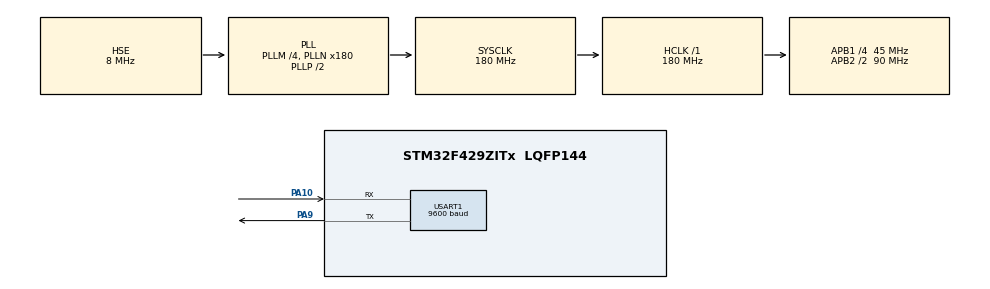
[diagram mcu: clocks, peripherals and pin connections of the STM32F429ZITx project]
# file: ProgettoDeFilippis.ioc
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ADC1.Channel-0\#ChannelRegularConversion=ADC_CHANNEL_TEMPSENSOR
ADC1.ClockPrescaler=ADC_CLOCK_SYNC_PCLK_DIV4
ADC1.ContinuousConvMode=DISABLE
ADC1.DMAContinuousRequests=DISABLE
ADC1.DataAlign=ADC_DATAALIGN_RIGHT
ADC1.DiscontinuousConvMode=DISABLE
ADC1.EOCSelection=ADC_EOC_SINGLE_CONV
ADC1.EnableAnalogWatchDog=false
ADC1.ExternalTrigConv=ADC_EXTERNALTRIGCONV_T2_TRGO
ADC1.ExternalTrigConvEdge=ADC_EXTERNALTRIGCONVEDGE_RISING
ADC1.InjNumberOfConversion=0
ADC1.NbrOfConversion=1
ADC1.NbrOfConversionFlag=1
ADC1.Rank-0\#ChannelRegularConversion=1
ADC1.Resolution=ADC_RESOLUTION_12B
ADC1.SamplingTime-0\#ChannelRegularConversion=ADC_SAMPLETIME_3CYCLES
ADC1.ScanConvMode=DISABLE
ADC1.master=1
Mcu.Family=STM32F4
Mcu.Name=STM32F429ZITx
Mcu.Package=LQFP144
NVIC.ADC_IRQn=true\:0\:0\:false\:false\:true\:true
NVIC.PriorityGroup=NVIC_PRIORITYGROUP_4
NVIC.TIM2_IRQn=true\:0\:0\:false\:false\:true\:true
PA10.Mode=Asynchronous
PA10.Signal=USART1_RX
PA9.Mode=Asynchronous
PA9.Signal=USART1_TX
PH0/OSC_IN.Mode=HSE-External-Oscillator
PH0/OSC_IN.Signal=RCC_OSC_IN
PH1/OSC_OUT.Mode=HSE-External-Oscillator
PH1/OSC_OUT.Signal=RCC_OSC_OUT
ProjectManager.HeapSize=0x200
ProjectManager.StackSize=0x400
ProjectManager.TargetToolchain=TrueSTUDIO
RCC.48MHZClocksFreq_Value=90000000
RCC.AHBFreq_Value=180000000
RCC.APB1CLKDivider=RCC_HCLK_DIV4
RCC.APB1Freq_Value=45000000
RCC.APB1TimFreq_Value=90000000
RCC.APB2CLKDivider=RCC_HCLK_DIV2
RCC.APB2Freq_Value=90000000
RCC.APB2TimFreq_Value=180000000
RCC.CortexFreq_Value=180000000
RCC.HCLKFreq_Value=180000000
RCC.HSE_VALUE=8000000
RCC.HSI_VALUE=16000000
RCC.LSE_VALUE=32768
RCC.PLLM=4
RCC.PLLN=180
RCC.PLLSourceVirtual=RCC_PLLSOURCE_HSE
RCC.SYSCLKFreq_VALUE=180000000
RCC.SYSCLKSource=RCC_SYSCLKSOURCE_PLLCLK
RCC.VCOOutputFreq_Value=360000000
TIM2.Period=4999
TIM2.Prescaler=9000
TIM2.TIM_MasterOutputTrigger=TIM_TRGO_UPDATE
USART1.BaudRate=9600
USART1.VirtualMode=VM_ASYNC
VP_ADC1_TempSens_Input.Mode=IN-TempSens
VP_TIM2_VS_ClockSourceINT.Mode=Internal
board=ProgettoDeFilippis

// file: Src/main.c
/**
  ******************************************************************************
  * @file           : main.c
  * @brief          : Main program body
  * ingroup 		: template
  * version 		: 1.0.0
  * date    		: 31/05/2018
  * author  		: Giovanni Caiazzo , Olawale Luqman Ajani, Luca Signorelli
  * defgroup 		: Matrix_Temperature
  *
  ******************************************************************************
  ** This notice applies to any and all portions of this file
  * that are not between comment pairs USER CODE BEGIN and
  * USER CODE END. Other portions of this file, whether
  * inserted by the user or by software development tools
  * are owned by their respective copyright owners.
  *
  * COPYRIGHT(c) 2018 STMicroelectronics
  *
  * Redistribution and use in source and binary forms, with or without modification,
  * are permitted provided that the following conditions are met:
  *   1. Redistributions of source code must retain the above copyright notice,
  *      this list of conditions and the following disclaimer.
  *   2. Redistributions in binary form must reproduce the above copyright notice,
  *      this list of conditions and the following disclaimer in the documentation
  *      and/or other materials provided with the distribution.
  *   3. Neither the name of STMicroelectronics nor the names of its contributors
  *      may be used to endorse or promote products derived from this software
  *      without specific prior written permission.
  *
  * THIS SOFTWARE IS PROVIDED BY THE COPYRIGHT HOLDERS AND CONTRIBUTORS "AS IS"
  * AND ANY EXPRESS OR IMPLIED WARRANTIES, INCLUDING, BUT NOT LIMITED TO, THE
  * IMPLIED WARRANTIES OF MERCHANTABILITY AND FITNESS FOR A PARTICULAR PURPOSE ARE
  * DISCLAIMED. IN NO EVENT SHALL THE COPYRIGHT HOLDER OR CONTRIBUTORS BE LIABLE
  * FOR ANY DIRECT, INDIRECT, INCIDENTAL, SPECIAL, EXEMPLARY, OR CONSEQUENTIAL
  * DAMAGES (INCLUDING, BUT NOT LIMITED TO, PROCUREMENT OF SUBSTITUTE GOODS OR
  * SERVICES; LOSS OF USE, DATA, OR PROFITS; OR BUSINESS INTERRUPTION) HOWEVER
  * CAUSED AND ON ANY THEORY OF LIABILITY, WHETHER IN CONTRACT, STRICT LIABILITY,
  * OR TORT (INCLUDING NEGLIGENCE OR OTHERWISE) ARISING IN ANY WAY OUT OF THE USE
  * OF THIS SOFTWARE, EVEN IF ADVISED OF THE POSSIBILITY OF SUCH DAMAGE.
  *
  ******************************************************************************
  */
#include "main.h"
#include "stm32f4xx_hal.h"
#include "adc.h"
#include "tim.h"
#include "usart.h"
#include "gpio.h"

/* USER CODE BEGIN PV */
/* Private variables ---------------------------------------------------------*/

/* **************** */
/* Global variables */
/* **************** */
/* The value of conversion process of ADC */
uint32_t tempReading 	= 0;

/* Timestamp of the sample*/
uint32_t timestamp 		= 0;

/* USER CODE END PV */

void SystemClock_Config(void);

/* USER CODE BEGIN PFP */
/* Private function prototypes -----------------------------------------------*/

/* USER CODE END PFP */

int main(void)
{

  /* MCU Configuration----------------------------------------------------------*/

  /* Reset of all peripherals, Initializes the Flash interface and the Systick. */
  HAL_Init();

  /* Configure the system clock */
  SystemClock_Config();

  /* Initialize all configured peripherals */
  MX_GPIO_Init();
  MX_ADC1_Init();
  MX_TIM2_Init();
  MX_USART1_UART_Init();
  /* USER CODE BEGIN 2 */
  HAL_TIM_Base_Start_IT(&htim2);
  HAL_ADC_Start_IT(&hadc1);
  /* USER CODE END 2 */

  /* Infinite loop */
  while (1)
  {

  }

}

void SystemClock_Config(void)
{

  RCC_OscInitTypeDef RCC_OscInitStruct;
  RCC_ClkInitTypeDef RCC_ClkInitStruct;

    /**Configure the main internal regulator output voltage
    */
  __HAL_RCC_PWR_CLK_ENABLE();

  __HAL_PWR_VOLTAGESCALING_CONFIG(PWR_REGULATOR_VOLTAGE_SCALE1);

    /**Initializes the CPU, AHB and APB busses clocks
    */
  RCC_OscInitStruct.OscillatorType = RCC_OSCILLATORTYPE_HSE;
  RCC_OscInitStruct.HSEState = RCC_HSE_ON;
  RCC_OscInitStruct.PLL.PLLState = RCC_PLL_ON;
  RCC_OscInitStruct.PLL.PLLSource = RCC_PLLSOURCE_HSE;
  RCC_OscInitStruct.PLL.PLLM = 4;
  RCC_OscInitStruct.PLL.PLLN = 180;
  RCC_OscInitStruct.PLL.PLLP = RCC_PLLP_DIV2;
  RCC_OscInitStruct.PLL.PLLQ = 4;
  if (HAL_RCC_OscConfig(&RCC_OscInitStruct) != HAL_OK)
  {
    _Error_Handler(__FILE__, __LINE__);
  }

    /**Activate the Over-Drive mode
    */
  if (HAL_PWREx_EnableOverDrive() != HAL_OK)
  {
    _Error_Handler(__FILE__, __LINE__);
  }

    /**Initializes the CPU, AHB and APB busses clocks
    */
  RCC_ClkInitStruct.ClockType = RCC_CLOCKTYPE_HCLK|RCC_CLOCKTYPE_SYSCLK
                              |RCC_CLOCKTYPE_PCLK1|RCC_CLOCKTYPE_PCLK2;
  RCC_ClkInitStruct.SYSCLKSource = RCC_SYSCLKSOURCE_PLLCLK;
  RCC_ClkInitStruct.AHBCLKDivider = RCC_SYSCLK_DIV1;
  RCC_ClkInitStruct.APB1CLKDivider = RCC_HCLK_DIV4;
  RCC_ClkInitStruct.APB2CLKDivider = RCC_HCLK_DIV2;

  if (HAL_RCC_ClockConfig(&RCC_ClkInitStruct, FLASH_LATENCY_5) != HAL_OK)
  {
    _Error_Handler(__FILE__, __LINE__);
  }

    /**Configure the Systick interrupt time
    */
  HAL_SYSTICK_Config(HAL_RCC_GetHCLKFreq()/1000);

    /**Configure the Systick
    */
  HAL_SYSTICK_CLKSourceConfig(SYSTICK_CLKSOURCE_HCLK);

  /* SysTick_IRQn interrupt configuration */
  HAL_NVIC_SetPriority(SysTick_IRQn, 0, 0);
}

/* USER CODE BEGIN 4 */

/* ************** */
/* Local Function */
/* ************** */
/*!
brief: 	Print a value of the temperature and its timestamp*/
/*!file:	main.c*/
/*! @param  value:		the value of the temperature in degrees centigrade*/
/*! @param  message:	the message prints of the console with the timestamp*/
/*! @retval None
  */
void PrintValues(float value, char message[40]) {

	/*! Compute the value of the temperature*/
	uint32_t decimal = timestamp%2*5;

	/*! Compute the value of the seconds */
	uint32_t sec = timestamp/2;

	/*! Compute the value of the minutes */
	uint32_t min = sec/60;

	/*! Compute the value of the hours */
	uint32_t hour = sec/3600;

	if (sec >= 60) {
		sec = 0;
	}
	if (min >= 60) {
			min = 0;
	}
	if (hour >= 24) {
				hour = 0;
	}

	/*! Put the value of the temperature with timestamp into the message variable */
	sprintf(message, "T = %u C - %02lu:%02lu:%02lu.%lu 26th May 2018 \n\r", (int)value, hour, min, sec, decimal);

	/*! Transmit the value of the temperature with timestamp to the console of the UART peripheral*/
	HAL_UART_Transmit(&huart1, (uint8_t*)message, strlen(message), 100);
}

/* ************** */
/* Local Function */
/* ************** */
/*!
 brief: 	Regular conversion complete callback in non blocking mode.
 			Definition of the HAL_ADC_ConvCpltCallback function.
			This function takes the sample value from the ADC
 			and converts it to temperature in degrees centigrade*/
/*!file:		Drivers\STM32F4xx_HAL_Driver\Inc\stm32f4xx_hal_adc.c*/
/*!param:  	hadc pointer to a ADC_HandleTypeDef structure that contains
         	the configuration information for the specified ADC.*/
/*!retval: 	None*/

void HAL_ADC_ConvCpltCallback(ADC_HandleTypeDef* hadc) {
	float vin = 0; 					/*< This store vin */
	float value = 0;				/*< This store value */
	char message[40] = {0};			/*< This store message */

	/*! Get the value of conversion process of ADC */
	tempReading = HAL_ADC_GetValue(hadc);

	/*! Conversion of value to volts in float  */
	vin = ((float)tempReading/4095.0)*VREF;

	/*! Conversion of value to temperature degrees centigrade in float  */
	value = (((float)vin - V25)/SLOPE) + 25.0;

	/*! Print a value of the temperature and its timestamp   */
	PrintValues(value, message);
}

/* USER CODE END 4 */

void _Error_Handler(char *file, int line)
{
  while(1)
  {
  }
}

/************************ (C) COPYRIGHT STMicroelectronics *****END OF FILE****/
